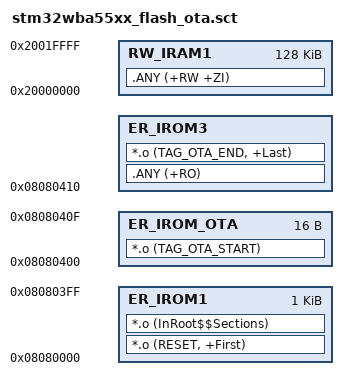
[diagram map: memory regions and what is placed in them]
; *************************************************************
; *** Scatter-Loading Description File generated by uVision ***
; *************************************************************

; Flash : 0x08080000 to 0x080FFFFF
LR_IROM1 0x08080000 0x00000400  
{    
  ; load address = execution address
  ER_IROM1      0x08080000 0x00000400  
  {  
    *.o (RESET, +First)
    *.o (InRoot$$Sections)
  }
}
  
LR_IROM2 0x08080400 0x00000010
{
  ER_IROM_OTA    0x08080400 0x00000010  
  {  
    *.o (TAG_OTA_START)
  }
}

LR_IROM3 0x08080410 ( 0x00080000 - 0x410 )
{
  ER_IROM3      0x08080410 
  {  
    .ANY (+RO)
    *.o (TAG_OTA_END, +Last)
  }
    
  ; RW data RAM1 : 0x20000000 to 0x2001FFFF
  RW_IRAM1      0x20000000 0x00020000
  {  
   .ANY (+RW +ZI)
  }
}

